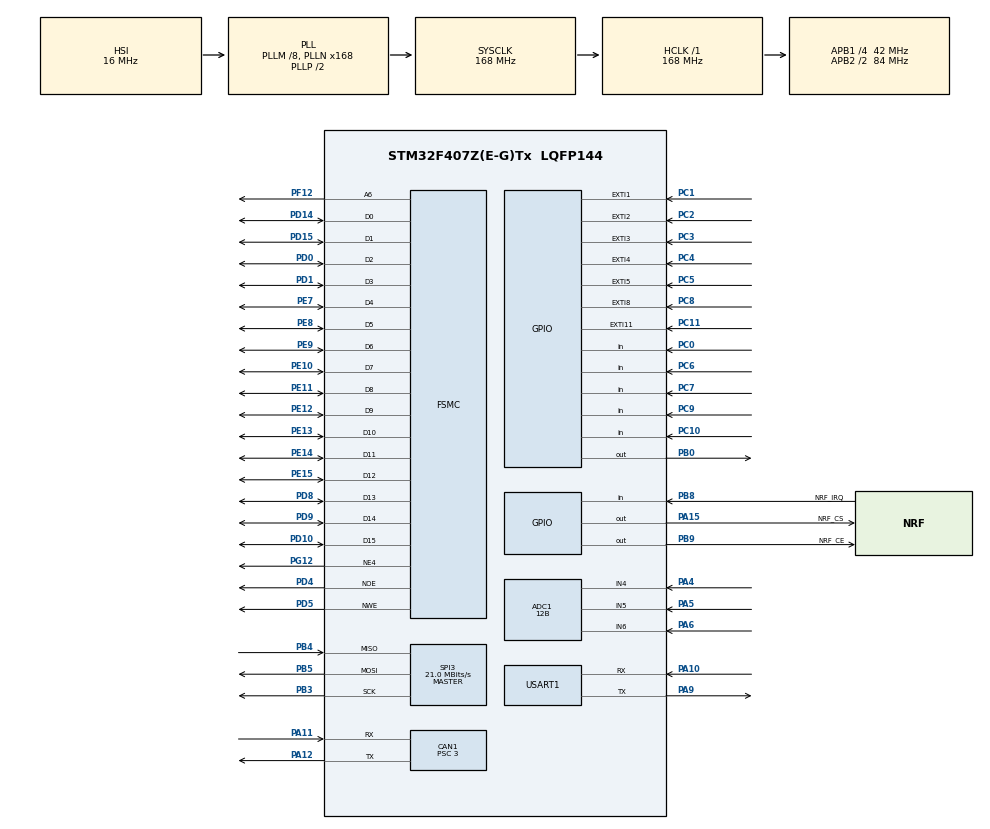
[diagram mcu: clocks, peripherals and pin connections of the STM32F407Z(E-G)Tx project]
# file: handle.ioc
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ADC1.Channel-4\#ChannelRegularConversion=ADC_CHANNEL_5
ADC1.Channel-5\#ChannelRegularConversion=ADC_CHANNEL_6
ADC1.Channel-6\#ChannelRegularConversion=ADC_CHANNEL_4
ADC1.ClockPrescaler=ADC_CLOCK_SYNC_PCLK_DIV4
ADC1.ContinuousConvMode=ENABLE
ADC1.DMAContinuousRequests=ENABLE
ADC1.DataAlign=ADC_DATAALIGN_RIGHT
ADC1.DiscontinuousConvMode=DISABLE
ADC1.EOCSelection=ADC_EOC_SINGLE_CONV
ADC1.EnableAnalogWatchDog=false
ADC1.ExternalTrigConv=ADC_SOFTWARE_START
ADC1.ExternalTrigConvEdge=ADC_EXTERNALTRIGCONVEDGE_NONE
ADC1.InjNumberOfConversion=0
ADC1.NbrOfConversion=3
ADC1.NbrOfConversionFlag=1
ADC1.Rank-4\#ChannelRegularConversion=1
ADC1.Rank-5\#ChannelRegularConversion=2
ADC1.Rank-6\#ChannelRegularConversion=3
ADC1.Resolution=ADC_RESOLUTION_12B
ADC1.SamplingTime-4\#ChannelRegularConversion=ADC_SAMPLETIME_3CYCLES
ADC1.SamplingTime-5\#ChannelRegularConversion=ADC_SAMPLETIME_3CYCLES
ADC1.SamplingTime-6\#ChannelRegularConversion=ADC_SAMPLETIME_3CYCLES
ADC1.ScanConvMode=ENABLE
ADC1.master=1
CAN1.ABOM=DISABLE
CAN1.AWUM=DISABLE
CAN1.BS1=CAN_BS1_9TQ
CAN1.BS2=CAN_BS2_4TQ
CAN1.CalculateTimeQuantum=71.42857142857143
CAN1.Mode=CAN_MODE_NORMAL
CAN1.NART=DISABLE
CAN1.Prescaler=3
CAN1.RFLM=DISABLE
CAN1.TTCM=DISABLE
CAN1.TXFP=DISABLE
Dma.ADC1.0.Direction=DMA_PERIPH_TO_MEMORY
Dma.ADC1.0.FIFOMode=DMA_FIFOMODE_DISABLE
Dma.ADC1.0.Instance=DMA2_Stream0
Dma.ADC1.0.MemDataAlignment=DMA_MDATAALIGN_WORD
Dma.ADC1.0.MemInc=DMA_MINC_ENABLE
Dma.ADC1.0.Mode=DMA_CIRCULAR
Dma.ADC1.0.PeriphDataAlignment=DMA_PDATAALIGN_WORD
Dma.ADC1.0.PeriphInc=DMA_PINC_DISABLE
Dma.ADC1.0.Priority=DMA_PRIORITY_HIGH
Dma.Request0=ADC1
Mcu.Family=STM32F4
Mcu.Name=STM32F407Z(E-G)Tx
Mcu.Package=LQFP144
NVIC.ADC_IRQn=true\:0\:0\:false\:false\:true\:true\:true
NVIC.CAN1_RX0_IRQn=true\:0\:0\:false\:false\:true\:true\:true
NVIC.CAN1_RX1_IRQn=true\:0\:0\:false\:false\:true\:true\:true
NVIC.CAN1_SCE_IRQn=true\:0\:0\:false\:false\:true\:true\:true
NVIC.DMA2_Stream0_IRQn=true\:0\:0\:false\:false\:true\:false\:true
NVIC.EXTI15_10_IRQn=true\:0\:0\:false\:false\:true\:true\:true
NVIC.EXTI1_IRQn=true\:0\:0\:false\:false\:true\:true\:true
NVIC.EXTI2_IRQn=true\:0\:0\:false\:false\:true\:true\:true
NVIC.EXTI3_IRQn=true\:0\:0\:false\:false\:true\:true\:true
NVIC.EXTI4_IRQn=true\:0\:0\:false\:false\:true\:true\:true
NVIC.EXTI9_5_IRQn=true\:0\:0\:false\:false\:true\:true\:true
NVIC.PriorityGroup=NVIC_PRIORITYGROUP_4
PA10.Mode=Asynchronous
PA10.Signal=USART1_RX
PA11.Mode=Master
PA11.Signal=CAN1_RX
PA12.Mode=Master
PA12.Signal=CAN1_TX
PA13.Mode=Serial_Wire
PA13.Signal=SYS_JTMS-SWDIO
PA14.Mode=Serial_Wire
PA14.Signal=SYS_JTCK-SWCLK
PA15.GPIO_Label=NRF_CS
PA15.Signal=GPIO_Output
PA4.Signal=ADCx_IN4
PA5.Signal=ADCx_IN5
PA6.Signal=ADCx_IN6
PA9.Mode=Asynchronous
PA9.Signal=USART1_TX
PB0.Signal=GPIO_Output
PB3.Mode=Full_Duplex_Master
PB3.Signal=SPI3_SCK
PB4.Mode=Full_Duplex_Master
PB4.Signal=SPI3_MISO
PB5.Mode=Full_Duplex_Master
PB5.Signal=SPI3_MOSI
PB8.GPIO_Label=NRF_IRQ
PB8.Signal=GPIO_Input
PB9.GPIO_Label=NRF_CE
PB9.Signal=GPIO_Output
PC0.Signal=GPIO_Input
PC1.GPIO_ModeDefaultEXTI=GPIO_MODE_IT_FALLING
PC1.Signal=GPXTI1
PC10.Signal=GPIO_Input
PC11.GPIO_ModeDefaultEXTI=GPIO_MODE_IT_RISING_FALLING
PC11.Signal=GPXTI11
PC2.GPIO_ModeDefaultEXTI=GPIO_MODE_IT_FALLING
PC2.Signal=GPXTI2
PC3.GPIO_ModeDefaultEXTI=GPIO_MODE_IT_FALLING
PC3.Signal=GPXTI3
PC4.GPIO_ModeDefaultEXTI=GPIO_MODE_IT_FALLING
PC4.Signal=GPXTI4
PC5.GPIO_ModeDefaultEXTI=GPIO_MODE_IT_FALLING
PC5.Signal=GPXTI5
PC6.Signal=GPIO_Input
PC7.Signal=GPIO_Input
PC8.GPIO_ModeDefaultEXTI=GPIO_MODE_IT_FALLING
PC8.Signal=GPXTI8
PC9.Signal=GPIO_Input
PD0.Signal=FSMC_D2_DA2
PD1.Signal=FSMC_D3_DA3
PD10.Signal=FSMC_D15_DA15
PD14.Signal=FSMC_D0_DA0
PD15.Signal=FSMC_D1_DA1
PD4.Signal=FSMC_NOE
PD5.Signal=FSMC_NWE
PD8.Signal=FSMC_D13_DA13
PD9.Signal=FSMC_D14_DA14
PE10.Signal=FSMC_D7_DA7
PE11.Signal=FSMC_D8_DA8
PE12.Signal=FSMC_D9_DA9
PE13.Signal=FSMC_D10_DA10
PE14.Signal=FSMC_D11_DA11
PE15.Signal=FSMC_D12_DA12
PE7.Signal=FSMC_D4_DA4
PE8.Signal=FSMC_D5_DA5
PE9.Signal=FSMC_D6_DA6
PF12.Signal=FSMC_A6
PG12.Mode=NorPsramChipSelect4_1
PG12.Signal=FSMC_NE4
PH0-OSC_IN.Mode=HSE-External-Oscillator
PH0-OSC_IN.Signal=RCC_OSC_IN
PH1-OSC_OUT.Mode=HSE-External-Oscillator
PH1-OSC_OUT.Signal=RCC_OSC_OUT
ProjectManager.HeapSize=0x200
ProjectManager.StackSize=0x400
ProjectManager.TargetToolchain=EWARM V8
RCC.48MHZClocksFreq_Value=84000000
RCC.AHBFreq_Value=168000000
RCC.APB1CLKDivider=RCC_HCLK_DIV4
RCC.APB1Freq_Value=42000000
RCC.APB1TimFreq_Value=84000000
RCC.APB2CLKDivider=RCC_HCLK_DIV2
RCC.APB2Freq_Value=84000000
RCC.APB2TimFreq_Value=168000000
RCC.CortexFreq_Value=168000000
RCC.HCLKFreq_Value=168000000
RCC.HSE_VALUE=8000000
RCC.HSI_VALUE=16000000
RCC.LSE_VALUE=32768
RCC.PLLM=8
RCC.PLLN=168
RCC.SYSCLKFreq_VALUE=168000000
RCC.SYSCLKSource=RCC_SYSCLKSOURCE_PLLCLK
RCC.VCOOutputFreq_Value=336000000
SH.ADCx_IN4.0=ADC1_IN4,IN4
SH.ADCx_IN5.0=ADC1_IN5,IN5
SH.ADCx_IN6.0=ADC1_IN6,IN6
SH.FSMC_A6.0=FSMC_A6,A6_1
SH.FSMC_D0_DA0.0=FSMC_D0,16b-d1
SH.FSMC_D10_DA10.0=FSMC_D10,16b-d1
SH.FSMC_D11_DA11.0=FSMC_D11,16b-d1
SH.FSMC_D12_DA12.0=FSMC_D12,16b-d1
SH.FSMC_D13_DA13.0=FSMC_D13,16b-d1
SH.FSMC_D14_DA14.0=FSMC_D14,16b-d1
SH.FSMC_D15_DA15.0=FSMC_D15,16b-d1
SH.FSMC_D1_DA1.0=FSMC_D1,16b-d1
SH.FSMC_D2_DA2.0=FSMC_D2,16b-d1
SH.FSMC_D3_DA3.0=FSMC_D3,16b-d1
SH.FSMC_D4_DA4.0=FSMC_D4,16b-d1
SH.FSMC_D5_DA5.0=FSMC_D5,16b-d1
SH.FSMC_D6_DA6.0=FSMC_D6,16b-d1
SH.FSMC_D7_DA7.0=FSMC_D7,16b-d1
SH.FSMC_D8_DA8.0=FSMC_D8,16b-d1
SH.FSMC_D9_DA9.0=FSMC_D9,16b-d1
SH.FSMC_NOE.0=FSMC_NOE,Lcd1
SH.FSMC_NWE.0=FSMC_NWE,Lcd1
SPI3.BaudRatePrescaler=SPI_BAUDRATEPRESCALER_2
SPI3.CalculateBaudRate=21.0 MBits/s
SPI3.Direction=SPI_DIRECTION_2LINES
SPI3.Mode=SPI_MODE_MASTER
SPI3.VirtualType=VM_MASTER
USART1.VirtualMode=VM_ASYNC
board=custom

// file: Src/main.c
/* USER CODE BEGIN Header */
/**
  ******************************************************************************
  * @file           : main.c
  * @brief          : Main program body
  ******************************************************************************
  * @attention
  *
  * <h2><center>&copy; Copyright (c) 2020 STMicroelectronics.
  * All rights reserved.</center></h2>
  *
  * This software component is licensed by ST under BSD 3-Clause license,
  * the "License"; You may not use this file except in compliance with the
  * License. You may obtain a copy of the License at:
  *                        opensource.org/licenses/BSD-3-Clause
  *
  ******************************************************************************
  */
/* USER CODE END Header */

#include "main.h"
#include "adc.h"
#include "can.h"
#include "dma.h"
#include "spi.h"
#include "usart.h"
#include "gpio.h"
#include "fsmc.h"
#include "adc_func.h"

/* USER CODE BEGIN Includes */
#include "nrf_comm.h"
/* USER CODE END Includes */

void SystemClock_Config(void);

/* USER CODE BEGIN 0 */
static uint16_t time_1ms_cnt = 0;

/* USER CODE END 0 */

int main(void)
{

  /* MCU Configuration--------------------------------------------------------*/

  /* Reset of all peripherals, Initializes the Flash interface and the Systick. */
  HAL_Init();

  /* Configure the system clock */
  SystemClock_Config();

  /* Initialize all configured peripherals */
  MX_GPIO_Init();
  MX_DMA_Init();
  MX_USART1_UART_Init();
  MX_CAN1_Init();
  MX_ADC1_Init();
  MX_FSMC_Init();
  MX_SPI3_Init();
  /* USER CODE BEGIN 2 */
  uint8_t nrf_addr[5] = {48, 51, 51, 48, 30};
  nrf_set_rx_addr(NRF_PIPE_0, nrf_addr, 5);
  nrf_set_tx_addr(nrf_addr, 5);
  nrf_init(NULL);
  HAL_ADC_Start(&hadc1);
  HAL_ADC_Start_DMA(&hadc1,(uint32_t *)&adc_rocker_value,5);

  /* USER CODE END 2 */

  /* Infinite loop */
    while (1) {
        adc_exe();
        gpio_delayed_button();
        nrf_main();
    }
}

void SystemClock_Config(void)
{
  RCC_OscInitTypeDef RCC_OscInitStruct = {0};
  RCC_ClkInitTypeDef RCC_ClkInitStruct = {0};

  /** Configure the main internal regulator output voltage
  */
  __HAL_RCC_PWR_CLK_ENABLE();
  __HAL_PWR_VOLTAGESCALING_CONFIG(PWR_REGULATOR_VOLTAGE_SCALE1);
  /** Initializes the CPU, AHB and APB busses clocks
  */
  RCC_OscInitStruct.OscillatorType = RCC_OSCILLATORTYPE_HSI;
  RCC_OscInitStruct.HSIState = RCC_HSI_ON;
  RCC_OscInitStruct.HSICalibrationValue = RCC_HSICALIBRATION_DEFAULT;
  RCC_OscInitStruct.PLL.PLLState = RCC_PLL_ON;
  RCC_OscInitStruct.PLL.PLLSource = RCC_PLLSOURCE_HSI;
  RCC_OscInitStruct.PLL.PLLM = 8;
  RCC_OscInitStruct.PLL.PLLN = 168;
  RCC_OscInitStruct.PLL.PLLP = RCC_PLLP_DIV2;
  RCC_OscInitStruct.PLL.PLLQ = 4;
  if (HAL_RCC_OscConfig(&RCC_OscInitStruct) != HAL_OK)
  {
    Error_Handler();
  }
  /** Initializes the CPU, AHB and APB busses clocks
  */
  RCC_ClkInitStruct.ClockType = RCC_CLOCKTYPE_HCLK|RCC_CLOCKTYPE_SYSCLK
                              |RCC_CLOCKTYPE_PCLK1|RCC_CLOCKTYPE_PCLK2;
  RCC_ClkInitStruct.SYSCLKSource = RCC_SYSCLKSOURCE_PLLCLK;
  RCC_ClkInitStruct.AHBCLKDivider = RCC_SYSCLK_DIV1;
  RCC_ClkInitStruct.APB1CLKDivider = RCC_HCLK_DIV4;
  RCC_ClkInitStruct.APB2CLKDivider = RCC_HCLK_DIV2;

  if (HAL_RCC_ClockConfig(&RCC_ClkInitStruct, FLASH_LATENCY_5) != HAL_OK)
  {
    Error_Handler();
  }
}

/* USER CODE BEGIN 4 */
void HAL_IncTick() {
    time_1ms_cnt++;
    if(time_1ms_cnt%10==0){
        //time_5ms_flag=1;
        adc_flag = 1;
    }
    if (time_1ms_cnt == 10000) {
        time_1ms_cnt = 0;
    }
}

/* USER CODE END 4 */

void Error_Handler(void)
{
}

/************************ (C) COPYRIGHT STMicroelectronics *****END OF FILE****/
